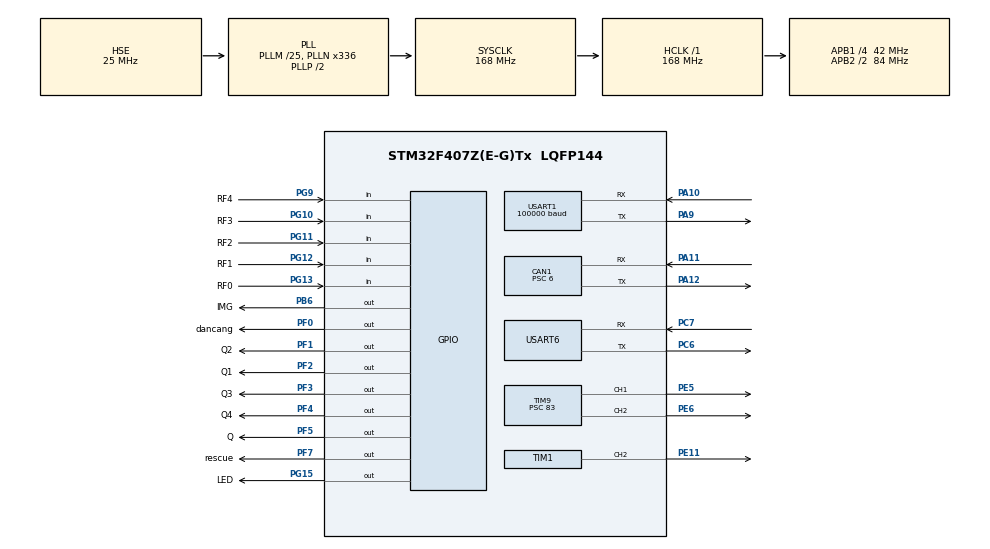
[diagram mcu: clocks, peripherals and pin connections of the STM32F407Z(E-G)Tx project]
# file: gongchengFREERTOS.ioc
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CAN1.BS1=CAN_BS1_3TQ
CAN1.BS2=CAN_BS2_3TQ
CAN1.CalculateTimeQuantum=142.85714285714286
CAN1.Prescaler=6
CAN1.TXFP=ENABLE
Dma.Request0=USART1_RX
Dma.Request1=USART6_TX
Dma.USART1_RX.0.Direction=DMA_PERIPH_TO_MEMORY
Dma.USART1_RX.0.FIFOMode=DMA_FIFOMODE_DISABLE
Dma.USART1_RX.0.Instance=DMA2_Stream2
Dma.USART1_RX.0.MemDataAlignment=DMA_MDATAALIGN_BYTE
Dma.USART1_RX.0.MemInc=DMA_MINC_ENABLE
Dma.USART1_RX.0.Mode=DMA_NORMAL
Dma.USART1_RX.0.PeriphDataAlignment=DMA_PDATAALIGN_BYTE
Dma.USART1_RX.0.PeriphInc=DMA_PINC_DISABLE
Dma.USART1_RX.0.Priority=DMA_PRIORITY_LOW
Dma.USART6_TX.1.Direction=DMA_MEMORY_TO_PERIPH
Dma.USART6_TX.1.FIFOMode=DMA_FIFOMODE_DISABLE
Dma.USART6_TX.1.Instance=DMA2_Stream6
Dma.USART6_TX.1.MemDataAlignment=DMA_MDATAALIGN_BYTE
Dma.USART6_TX.1.MemInc=DMA_MINC_ENABLE
Dma.USART6_TX.1.Mode=DMA_NORMAL
Dma.USART6_TX.1.PeriphDataAlignment=DMA_PDATAALIGN_BYTE
Dma.USART6_TX.1.PeriphInc=DMA_PINC_DISABLE
Dma.USART6_TX.1.Priority=DMA_PRIORITY_MEDIUM
FREERTOS.INCLUDE_vTaskDelayUntil=1
FREERTOS.Tasks01=defaultTask,0,128,StartDefaultTask,Default,NULL,Dynamic,NULL,NULL
Mcu.Family=STM32F4
Mcu.Name=STM32F407Z(E-G)Tx
Mcu.Package=LQFP144
NVIC.CAN1_RX0_IRQn=true\:6\:0\:true\:false\:true\:true\:true\:true
NVIC.DMA2_Stream2_IRQn=true\:5\:0\:false\:false\:true\:true\:true\:true
NVIC.DMA2_Stream6_IRQn=true\:5\:0\:false\:false\:true\:true\:true\:true
NVIC.PriorityGroup=NVIC_PRIORITYGROUP_4
NVIC.TIM8_TRG_COM_TIM14_IRQn=true\:0\:0\:false\:false\:true\:false\:false\:true
NVIC.TimeBase=TIM8_TRG_COM_TIM14_IRQn
NVIC.TimeBaseIP=TIM14
NVIC.USART1_IRQn=true\:5\:0\:false\:false\:true\:true\:true\:true
NVIC.USART6_IRQn=true\:6\:0\:true\:false\:true\:true\:true\:true
PA10.Mode=Asynchronous
PA10.Signal=USART1_RX
PA11.Mode=Master
PA11.Signal=CAN1_RX
PA12.Mode=Master
PA12.Signal=CAN1_TX
PA13.Mode=Serial_Wire
PA13.Signal=SYS_JTMS-SWDIO
PA14.Mode=Serial_Wire
PA14.Signal=SYS_JTCK-SWCLK
PA9.Mode=Asynchronous
PA9.Signal=USART1_TX
PB6.GPIO_Label=IMG
PB6.GPIO_ModeDefaultOutputPP=GPIO_MODE_OUTPUT_PP
PB6.GPIO_PuPd=GPIO_NOPULL
PB6.GPIO_Speed=GPIO_SPEED_FREQ_VERY_HIGH
PB6.Signal=GPIO_Output
PC6.Mode=Asynchronous
PC6.Signal=USART6_TX
PC7.Mode=Asynchronous
PC7.Signal=USART6_RX
PE11.Signal=S_TIM1_CH2
PE5.Signal=S_TIM9_CH1
PE6.Signal=S_TIM9_CH2
PF0.GPIO_Label=dancang
PF0.GPIO_Speed=GPIO_SPEED_FREQ_VERY_HIGH
PF0.PinState=GPIO_PIN_SET
PF0.Signal=GPIO_Output
PF1.GPIO_Label=Q2
PF1.GPIO_Speed=GPIO_SPEED_FREQ_VERY_HIGH
PF1.PinState=GPIO_PIN_SET
PF1.Signal=GPIO_Output
PF2.GPIO_Label=Q1
PF2.GPIO_Speed=GPIO_SPEED_FREQ_VERY_HIGH
PF2.PinState=GPIO_PIN_SET
PF2.Signal=GPIO_Output
PF3.GPIO_Label=Q3
PF3.GPIO_Speed=GPIO_SPEED_FREQ_VERY_HIGH
PF3.PinState=GPIO_PIN_SET
PF3.Signal=GPIO_Output
PF4.GPIO_Label=Q4
PF4.GPIO_Speed=GPIO_SPEED_FREQ_VERY_HIGH
PF4.PinState=GPIO_PIN_SET
PF4.Signal=GPIO_Output
PF5.GPIO_Label=Q
PF5.GPIO_Speed=GPIO_SPEED_FREQ_VERY_HIGH
PF5.PinState=GPIO_PIN_SET
PF5.Signal=GPIO_Output
PF7.GPIO_Label=rescue
PF7.GPIO_ModeDefaultOutputPP=GPIO_MODE_OUTPUT_PP
PF7.GPIO_PuPd=GPIO_NOPULL
PF7.GPIO_Speed=GPIO_SPEED_FREQ_VERY_HIGH
PF7.PinState=GPIO_PIN_SET
PF7.Signal=GPIO_Output
PG10.GPIO_Label=RF3
PG10.Signal=GPIO_Input
PG11.GPIO_Label=RF2
PG11.Signal=GPIO_Input
PG12.GPIO_Label=RF1
PG12.Signal=GPIO_Input
PG13.GPIO_Label=RF0
PG13.Signal=GPIO_Input
PG15.GPIO_Label=LED
PG15.GPIO_Speed=GPIO_SPEED_FREQ_VERY_HIGH
PG15.Signal=GPIO_Output
PG9.GPIO_Label=RF4
PG9.Signal=GPIO_Input
PH0-OSC_IN.Mode=HSE-External-Oscillator
PH0-OSC_IN.Signal=RCC_OSC_IN
PH1-OSC_OUT.Mode=HSE-External-Oscillator
PH1-OSC_OUT.Signal=RCC_OSC_OUT
ProjectManager.HeapSize=0x400
ProjectManager.StackSize=0x800
ProjectManager.TargetToolchain=MDK-ARM V5
RCC.48MHZClocksFreq_Value=84000000
RCC.AHBFreq_Value=168000000
RCC.APB1CLKDivider=RCC_HCLK_DIV4
RCC.APB1Freq_Value=42000000
RCC.APB1TimFreq_Value=84000000
RCC.APB2CLKDivider=RCC_HCLK_DIV2
RCC.APB2Freq_Value=84000000
RCC.APB2TimFreq_Value=168000000
RCC.CortexFreq_Value=168000000
RCC.HCLKFreq_Value=168000000
RCC.HSE_VALUE=25000000
RCC.HSI_VALUE=16000000
RCC.LSE_VALUE=32768
RCC.PLLM=25
RCC.PLLN=336
RCC.PLLSourceVirtual=RCC_PLLSOURCE_HSE
RCC.SYSCLKFreq_VALUE=168000000
RCC.SYSCLKSource=RCC_SYSCLKSOURCE_PLLCLK
RCC.VCOOutputFreq_Value=336000000
SH.S_TIM1_CH2.0=TIM1_CH2,PWM Generation2 CH2
SH.S_TIM9_CH1.0=TIM9_CH1,PWM Generation1 CH1
SH.S_TIM9_CH2.0=TIM9_CH2,PWM Generation2 CH2
TIM1.Channel-PWM\ Generation2\ CH2=TIM_CHANNEL_2
TIM1.Period=19999
TIM1.Prescaler=167
TIM1.Pulse-PWM\ Generation2\ CH2=720
TIM5.Period=0xffffffff
TIM5.Prescaler=839
TIM7.Period=0xffff
TIM7.Prescaler=8399
TIM9.Channel-PWM\ Generation1\ CH1=TIM_CHANNEL_1
TIM9.Channel-PWM\ Generation2\ CH2=TIM_CHANNEL_2
TIM9.Period=19999
TIM9.Prescaler=83
TIM9.Pulse-PWM\ Generation1\ CH1=2400
TIM9.Pulse-PWM\ Generation2\ CH2=500
USART1.BaudRate=100000
USART1.VirtualMode=VM_ASYNC
USART6.VirtualMode=VM_ASYNC
VP_FREERTOS_VS_CMSIS_V1.Mode=CMSIS_V1
VP_SYS_VS_tim14.Mode=TIM14
VP_TIM1_VS_ClockSourceINT.Mode=Internal
VP_TIM5_VS_ClockSourceINT.Mode=Internal
VP_TIM7_VS_ClockSourceINT.Mode=Enable_Timer
VP_TIM9_VS_ClockSourceINT.Mode=Internal
board=custom

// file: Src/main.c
/* USER CODE BEGIN Header */
/**
  ******************************************************************************
  * @file           : main.c
  * @brief          : Main program body
  ******************************************************************************
  * This notice applies to any and all portions of this file
  * that are not between comment pairs USER CODE BEGIN and
  * USER CODE END. Other portions of this file, whether
  * inserted by the user or by software development tools
  * are owned by their respective copyright owners.
  *
  * Copyright (c) 2019 STMicroelectronics International N.V.
  * All rights reserved.
  *
  * Redistribution and use in source and binary forms, with or without
  * modification, are permitted, provided that the following conditions are met:
  *
  * 1. Redistribution of source code must retain the above copyright notice,
  *    this list of conditions and the following disclaimer.
  * 2. Redistributions in binary form must reproduce the above copyright notice,
  *    this list of conditions and the following disclaimer in the documentation
  *    and/or other materials provided with the distribution.
  * 3. Neither the name of STMicroelectronics nor the names of other
  *    contributors to this software may be used to endorse or promote products
  *    derived from this software without specific written permission.
  * 4. This software, including modifications and/or derivative works of this
  *    software, must execute solely and exclusively on microcontroller or
  *    microprocessor devices manufactured by or for STMicroelectronics.
  * 5. Redistribution and use of this software other than as permitted under
  *    this license is void and will automatically terminate your rights under
  *    this license.
  *
  * THIS SOFTWARE IS PROVIDED BY STMICROELECTRONICS AND CONTRIBUTORS "AS IS"
  * AND ANY EXPRESS, IMPLIED OR STATUTORY WARRANTIES, INCLUDING, BUT NOT
  * LIMITED TO, THE IMPLIED WARRANTIES OF MERCHANTABILITY, FITNESS FOR A
  * PARTICULAR PURPOSE AND NON-INFRINGEMENT OF THIRD PARTY INTELLECTUAL PROPERTY
  * RIGHTS ARE DISCLAIMED TO THE FULLEST EXTENT PERMITTED BY LAW. IN NO EVENT
  * SHALL STMICROELECTRONICS OR CONTRIBUTORS BE LIABLE FOR ANY DIRECT, INDIRECT,
  * INCIDENTAL, SPECIAL, EXEMPLARY, OR CONSEQUENTIAL DAMAGES (INCLUDING, BUT NOT
  * LIMITED TO, PROCUREMENT OF SUBSTITUTE GOODS OR SERVICES; LOSS OF USE, DATA,
  * OR PROFITS; OR BUSINESS INTERRUPTION) HOWEVER CAUSED AND ON ANY THEORY OF
  * LIABILITY, WHETHER IN CONTRACT, STRICT LIABILITY, OR TORT (INCLUDING
  * NEGLIGENCE OR OTHERWISE) ARISING IN ANY WAY OUT OF THE USE OF THIS SOFTWARE,
  * EVEN IF ADVISED OF THE POSSIBILITY OF SUCH DAMAGE.
  *
  ******************************************************************************
  */
/* USER CODE END Header */

#include "main.h"
#include "cmsis_os.h"
#include "can.h"
#include "dma.h"
#include "tim.h"
#include "usart.h"
#include "gpio.h"

/* USER CODE BEGIN Includes */
#include "motor.h"
#include "test_can.h"
#include "Chassis.h"
#include <ROBOMODULE.h>

/* USER CODE END Includes */

void SystemClock_Config(void);
void MX_FREERTOS_Init(void);

int main(void)
{

  /* MCU Configuration--------------------------------------------------------*/

  /* Reset of all peripherals, Initializes the Flash interface and the Systick. */

  HAL_Init();

  /* Configure the system clock */
  SystemClock_Config();

  /* Initialize all configured peripherals */
  MX_GPIO_Init();
  MX_DMA_Init();
  MX_CAN1_Init();
  MX_USART1_UART_Init();
  MX_TIM1_Init();
  MX_TIM5_Init();
  MX_USART6_UART_Init();
  MX_TIM7_Init();
  MX_TIM9_Init();
  /* USER CODE BEGIN 2 */
	__HAL_UART_ENABLE_IT(&huart6,UART_IT_TC);
	ALL_Reset();

  /* USER CODE END 2 */

  /* Call init function for freertos objects (in freertos.c) */
  MX_FREERTOS_Init();

  /* Start scheduler */
  osKernelStart();

  /* We should never get here as control is now taken by the scheduler */

  /* Infinite loop */
  while (1)
  {

  }
}

void SystemClock_Config(void)
{
  RCC_OscInitTypeDef RCC_OscInitStruct = {0};
  RCC_ClkInitTypeDef RCC_ClkInitStruct = {0};

  /** Configure the main internal regulator output voltage
  */
  __HAL_RCC_PWR_CLK_ENABLE();
  __HAL_PWR_VOLTAGESCALING_CONFIG(PWR_REGULATOR_VOLTAGE_SCALE1);
  /** Initializes the CPU, AHB and APB busses clocks
  */
  RCC_OscInitStruct.OscillatorType = RCC_OSCILLATORTYPE_HSE;
  RCC_OscInitStruct.HSEState = RCC_HSE_ON;
  RCC_OscInitStruct.PLL.PLLState = RCC_PLL_ON;
  RCC_OscInitStruct.PLL.PLLSource = RCC_PLLSOURCE_HSE;
  RCC_OscInitStruct.PLL.PLLM = 25;
  RCC_OscInitStruct.PLL.PLLN = 336;
  RCC_OscInitStruct.PLL.PLLP = RCC_PLLP_DIV2;
  RCC_OscInitStruct.PLL.PLLQ = 4;
  if (HAL_RCC_OscConfig(&RCC_OscInitStruct) != HAL_OK)
  {
    Error_Handler();
  }
  /** Initializes the CPU, AHB and APB busses clocks
  */
  RCC_ClkInitStruct.ClockType = RCC_CLOCKTYPE_HCLK|RCC_CLOCKTYPE_SYSCLK
                              |RCC_CLOCKTYPE_PCLK1|RCC_CLOCKTYPE_PCLK2;
  RCC_ClkInitStruct.SYSCLKSource = RCC_SYSCLKSOURCE_PLLCLK;
  RCC_ClkInitStruct.AHBCLKDivider = RCC_SYSCLK_DIV1;
  RCC_ClkInitStruct.APB1CLKDivider = RCC_HCLK_DIV4;
  RCC_ClkInitStruct.APB2CLKDivider = RCC_HCLK_DIV2;

  if (HAL_RCC_ClockConfig(&RCC_ClkInitStruct, FLASH_LATENCY_5) != HAL_OK)
  {
    Error_Handler();
  }
}

void HAL_TIM_PeriodElapsedCallback(TIM_HandleTypeDef *htim)
{
  if (htim->Instance == TIM14) {
    HAL_IncTick();
  }
}

void Error_Handler(void)
{
}

/************************ (C) COPYRIGHT STMicroelectronics *****END OF FILE****/

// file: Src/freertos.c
/* USER CODE BEGIN Header */
/**
  ******************************************************************************
  * File Name          : freertos.c
  * Description        : Code for freertos applications
  ******************************************************************************
  * This notice applies to any and all portions of this file
  * that are not between comment pairs USER CODE BEGIN and
  * USER CODE END. Other portions of this file, whether
  * inserted by the user or by software development tools
  * are owned by their respective copyright owners.
  *
  * Copyright (c) 2019 STMicroelectronics International N.V.
  * All rights reserved.
  *
  * Redistribution and use in source and binary forms, with or without
  * modification, are permitted, provided that the following conditions are met:
  *
  * 1. Redistribution of source code must retain the above copyright notice,
  *    this list of conditions and the following disclaimer.
  * 2. Redistributions in binary form must reproduce the above copyright notice,
  *    this list of conditions and the following disclaimer in the documentation
  *    and/or other materials provided with the distribution.
  * 3. Neither the name of STMicroelectronics nor the names of other
  *    contributors to this software may be used to endorse or promote products
  *    derived from this software without specific written permission.
  * 4. This software, including modifications and/or derivative works of this
  *    software, must execute solely and exclusively on microcontroller or
  *    microprocessor devices manufactured by or for STMicroelectronics.
  * 5. Redistribution and use of this software other than as permitted under
  *    this license is void and will automatically terminate your rights under
  *    this license.
  *
  * THIS SOFTWARE IS PROVIDED BY STMICROELECTRONICS AND CONTRIBUTORS "AS IS"
  * AND ANY EXPRESS, IMPLIED OR STATUTORY WARRANTIES, INCLUDING, BUT NOT
  * LIMITED TO, THE IMPLIED WARRANTIES OF MERCHANTABILITY, FITNESS FOR A
  * PARTICULAR PURPOSE AND NON-INFRINGEMENT OF THIRD PARTY INTELLECTUAL PROPERTY
  * RIGHTS ARE DISCLAIMED TO THE FULLEST EXTENT PERMITTED BY LAW. IN NO EVENT
  * SHALL STMICROELECTRONICS OR CONTRIBUTORS BE LIABLE FOR ANY DIRECT, INDIRECT,
  * INCIDENTAL, SPECIAL, EXEMPLARY, OR CONSEQUENTIAL DAMAGES (INCLUDING, BUT NOT
  * LIMITED TO, PROCUREMENT OF SUBSTITUTE GOODS OR SERVICES; LOSS OF USE, DATA,
  * OR PROFITS; OR BUSINESS INTERRUPTION) HOWEVER CAUSED AND ON ANY THEORY OF
  * LIABILITY, WHETHER IN CONTRACT, STRICT LIABILITY, OR TORT (INCLUDING
  * NEGLIGENCE OR OTHERWISE) ARISING IN ANY WAY OUT OF THE USE OF THIS SOFTWARE,
  * EVEN IF ADVISED OF THE POSSIBILITY OF SUCH DAMAGE.
  *
  ******************************************************************************
  */
/* USER CODE END Header */

#include "FreeRTOS.h"
#include "task.h"
#include "main.h"
#include "cmsis_os.h"

/* USER CODE BEGIN Includes */
#include "FreeRTOSTask.h"

/* USER CODE END Includes */

osThreadId defaultTaskHandle;

void StartDefaultTask(void const * argument);

void MX_FREERTOS_Init(void); /* (MISRA C 2004 rule 8.1) */

/* GetIdleTaskMemory prototype (linked to static allocation support) */
void vApplicationGetIdleTaskMemory( StaticTask_t **ppxIdleTaskTCBBuffer, StackType_t **ppxIdleTaskStackBuffer, uint32_t *pulIdleTaskStackSize );

/* USER CODE BEGIN GET_IDLE_TASK_MEMORY */
static StaticTask_t xIdleTaskTCBBuffer;
static StackType_t xIdleStack[configMINIMAL_STACK_SIZE];

void vApplicationGetIdleTaskMemory( StaticTask_t **ppxIdleTaskTCBBuffer, StackType_t **ppxIdleTaskStackBuffer, uint32_t *pulIdleTaskStackSize )
{
  *ppxIdleTaskTCBBuffer = &xIdleTaskTCBBuffer;
  *ppxIdleTaskStackBuffer = &xIdleStack[0];
  *pulIdleTaskStackSize = configMINIMAL_STACK_SIZE;
  /* place for user code */
}
/* USER CODE END GET_IDLE_TASK_MEMORY */

void MX_FREERTOS_Init(void) {

  /* Create the thread(s) */
  /* definition and creation of defaultTask */
  osThreadDef(defaultTask, StartDefaultTask, osPriorityNormal, 0, 128);
  defaultTaskHandle = osThreadCreate(osThread(defaultTask), NULL);

}

void StartDefaultTask(void const * argument)
{

  /* USER CODE BEGIN StartDefaultTask */

	taskENTER_CRITICAL();           //�����ٽ���
	StartTask();
	vTaskDelete(NULL);
	taskEXIT_CRITICAL();            //�˳��ٽ���

  /* Infinite loop */
  for(;;)
  {
    osDelay(1);
  }
  /* USER CODE END StartDefaultTask */
}

/************************ (C) COPYRIGHT STMicroelectronics *****END OF FILE****/
